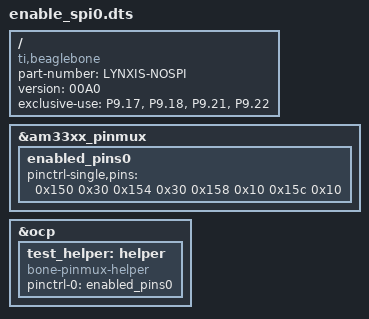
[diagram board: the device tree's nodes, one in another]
/dts-v1/;
/plugin/;

/ {
    compatible = "ti,beaglebone", "ti,beaglebone-black", "ti,beaglebone-green";
    part-number = "LYNXIS-NOSPI";
    version =  "00A0";
    exclusive-use = "P9.17", "P9.18", "P9.21", "P9.22";

    fragment@0 {
        target = <&am33xx_pinmux>;
        __overlay__ {
            enabled_pins0: enabled_pins0 {
                pinctrl-single,pins = <
                    0x150 0x30    /* spi0_sclk pin_input mode0 pullup */
                    0x154 0x30    /* spi0_d0 pin_input mode0 pullup */
                    0x158 0x10   /* spi0_d1 pin_output mode0 pullup */
                    0x15c 0x10   /* spi0_cs0 pin_output mode0 pullup */
                >;
            };
        };
    };
    fragment@1 {
        target = <&ocp>;
        __overlay__ {
            test_helper: helper {
                compatible = "bone-pinmux-helper";
                pinctrl-names = "default";
                pinctrl-0 = <&enabled_pins0>;
                status = "okay";
            };
        };
    };
};

